# HDSC_HC32F46X register map
Vendor: HDSC Co.,Ltd.; Series: ARMCM4; File version: 1.0
CPU: CM4 r0p1, little endian, MPU, FPU, 4 interrupt priority bits
Registers are 32-bit, read-write, reset 0x0 unless marked. A register's access mark holds for its fields unless they carry their own. Offsets are from the block's base; [hi:lo] are bit positions; {n}, {i} and the like mark numbered series.

## FCM
Base 0x40048400
0x00 LVR
  [15:0] LVR
0x04 UVR
  [15:0] UVR
0x08 CNTR ro
  [15:0] CNTR
0x0C STR
  [0] START
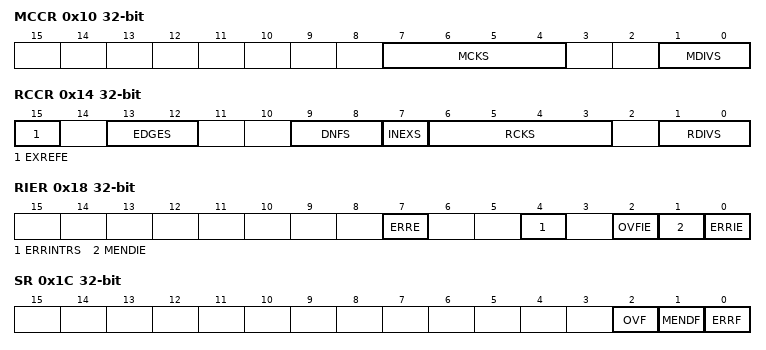
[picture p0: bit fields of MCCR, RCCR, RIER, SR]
0x10 MCCR
  [7:4] MCKS, [1:0] MDIVS
0x14 RCCR
  [15] EXREFE, [13:12] EDGES, [9:8] DNFS, [7] INEXS, [6:3] RCKS, [1:0] RDIVS
0x18 RIER
  [7] ERRE, [4] ERRINTRS, [2] OVFIE, [1] MENDIE, [0] ERRIE
0x1C SR ro
  [2] OVF, [1] MENDF, [0] ERRF
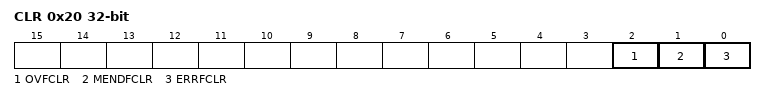
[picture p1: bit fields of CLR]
0x20 CLR wo
  [2] OVFCLR, [1] MENDFCLR, [0] ERRFCLR

## HASH
Base 0x40008400
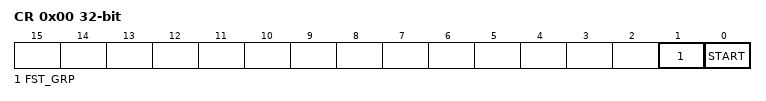
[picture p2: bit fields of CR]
0x00 CR
  [1] FST_GRP, [0] START
0x10 HR7
0x14 HR6
0x18 HR5
0x1C HR4
0x20 HR3
0x24 HR2
0x28 HR1
0x2C HR0
0x40 DR15
0x44 DR14
0x48 DR13
0x4C DR12
0x50 DR11
0x54 DR10
0x58 DR9
0x5C DR8
0x60 DR7
0x64 DR6
0x68 DR5
0x6C DR4
0x70 DR3
0x74 DR2
0x78 DR1
0x7C DR0

## I2C1 — desc I2C
Base 0x4004E000
Same registers: I2C2 0x4004E400, I2C3 0x4004E800
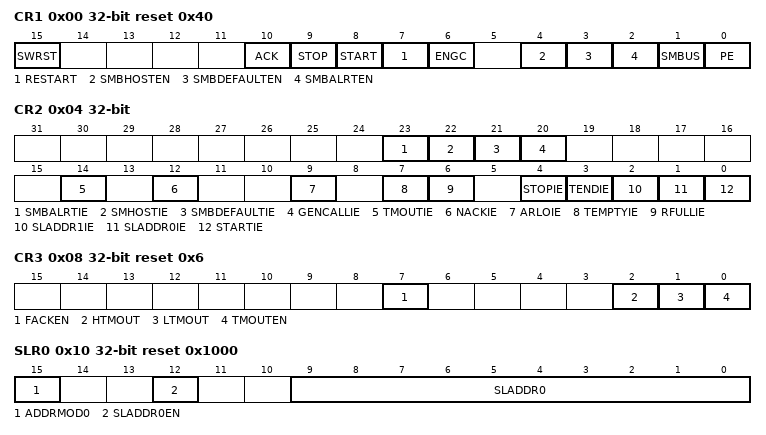
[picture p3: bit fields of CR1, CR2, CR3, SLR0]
0x00 CR1 reset 0x40
  [15] SWRST, [10] ACK, [9] STOP, [8] START, [7] RESTART, [6] ENGC, [4] SMBHOSTEN, [3] SMBDEFAULTEN, [2] SMBALRTEN, [1] SMBUS, [0] PE
0x04 CR2
  [23] SMBALRTIE, [22] SMHOSTIE, [21] SMBDEFAULTIE, [20] GENCALLIE, [14] TMOUTIE, [12] NACKIE, [9] ARLOIE, [7] TEMPTYIE, [6] RFULLIE, [4] STOPIE, [3] TENDIE, [2] SLADDR1IE, [1] SLADDR0IE, [0] STARTIE
0x08 CR3 reset 0x6
  [7] FACKEN, [2] HTMOUT, [1] LTMOUT, [0] TMOUTEN
0x10 SLR0 reset 0x1000
  [15] ADDRMOD0, [12] SLADDR0EN, [9:0] SLADDR0
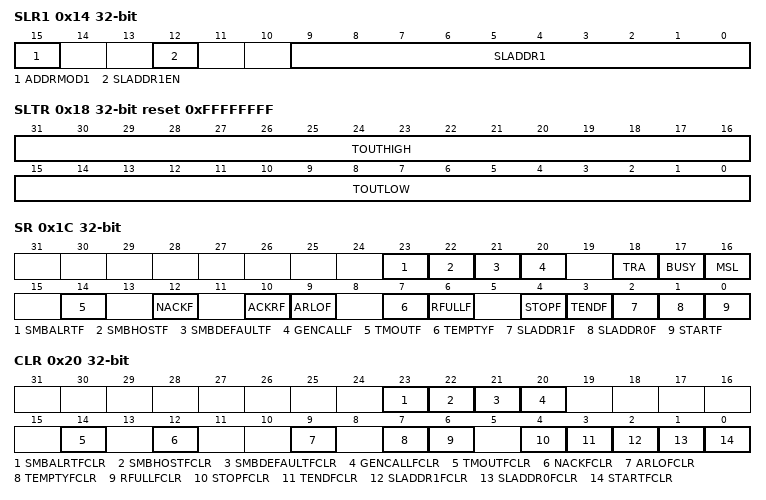
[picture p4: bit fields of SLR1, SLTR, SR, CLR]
0x14 SLR1
  [15] ADDRMOD1, [12] SLADDR1EN, [9:0] SLADDR1
0x18 SLTR reset 0xFFFFFFFF
  [31:16] TOUTHIGH, [15:0] TOUTLOW
0x1C SR
  [23] SMBALRTF, [22] SMBHOSTF, [21] SMBDEFAULTF, [20] GENCALLF, [18] TRA, [17] BUSY, [16] MSL, [14] TMOUTF, [12] NACKF, [10] ACKRF, [9] ARLOF, [7] TEMPTYF, [6] RFULLF, [4] STOPF, [3] TENDF, [2] SLADDR1F, [1] SLADDR0F, [0] STARTF
0x20 CLR wo
  [23] SMBALRTFCLR, [22] SMBHOSTFCLR, [21] SMBDEFAULTFCLR, [20] GENCALLFCLR, [14] TMOUTFCLR, [12] NACKFCLR, [9] ARLOFCLR, [7] TEMPTYFCLR, [6] RFULLFCLR, [4] STOPFCLR, [3] TENDFCLR, [2] SLADDR1FCLR, [1] SLADDR0FCLR, [0] STARTFCLR
0x24 DTR wo reset 0xFF
  [7:0] DT
0x28 DRR ro
  [7:0] DR
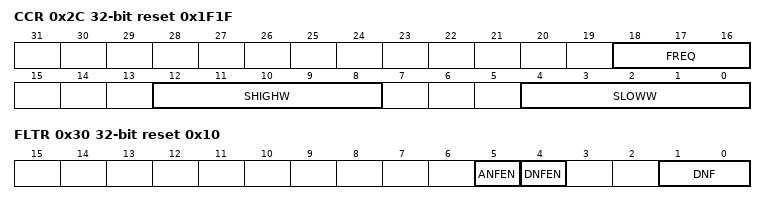
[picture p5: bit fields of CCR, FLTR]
0x2C CCR reset 0x1F1F
  [18:16] FREQ, [12:8] SHIGHW, [4:0] SLOWW
0x30 FLTR reset 0x10
  [5] ANFEN, [4] DNFEN, [1:0] DNF

## I2S1 — desc I2S
Base 0x4001E000
Same registers: I2S2 0x4001E400, I2S3 0x40022000, I2S4 0x40022400
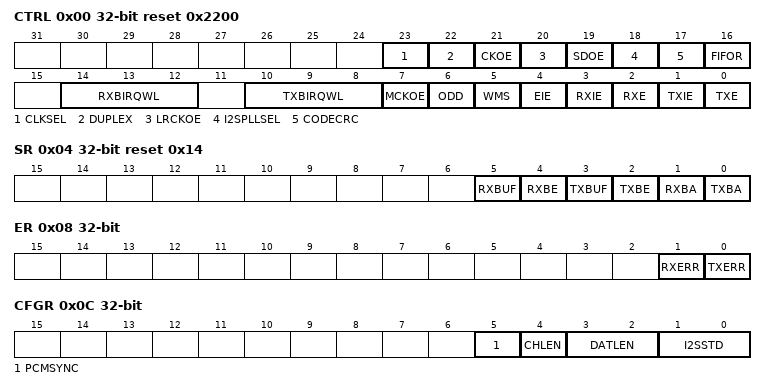
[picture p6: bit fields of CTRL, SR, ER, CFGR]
0x00 CTRL reset 0x2200
  [23] CLKSEL, [22] DUPLEX, [21] CKOE, [20] LRCKOE, [19] SDOE, [18] I2SPLLSEL, [17] CODECRC, [16] FIFOR, [14:12] RXBIRQWL, [10:8] TXBIRQWL, [7] MCKOE, [6] ODD, [5] WMS, [4] EIE, [3] RXIE, [2] RXE, [1] TXIE, [0] TXE
0x04 SR ro reset 0x14
  [5] RXBUF, [4] RXBE, [3] TXBUF, [2] TXBE, [1] RXBA, [0] TXBA
0x08 ER
  [1] RXERR, [0] TXERR
0x0C CFGR
  [5] PCMSYNC, [4] CHLEN, [3:2] DATLEN, [1:0] I2SSTD
0x10 TXBUF wo
0x14 RXBUF ro
0x18 PR reset 0x2
  [7:0] I2SDIV

## ICG
Base 0x00000400
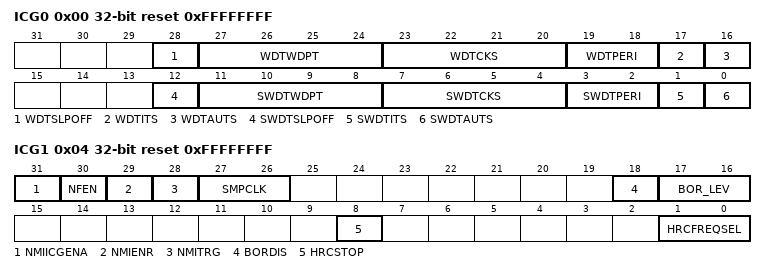
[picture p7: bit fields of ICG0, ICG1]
0x00 ICG0 ro reset 0xFFFFFFFF
  [28] WDTSLPOFF, [27:24] WDTWDPT, [23:20] WDTCKS, [19:18] WDTPERI, [17] WDTITS, [16] WDTAUTS, [12] SWDTSLPOFF, [11:8] SWDTWDPT, [7:4] SWDTCKS, [3:2] SWDTPERI, [1] SWDTITS, [0] SWDTAUTS
0x04 ICG1 ro reset 0xFFFFFFFF
  [31] NMIICGENA, [30] NFEN, [29] NMIENR, [28] NMITRG, [27:26] SMPCLK, [18] BORDIS, [17:16] BOR_LEV, [8] HRCSTOP, [1:0] HRCFREQSEL
{0x0+4i} ICG{i} ro reset 0xFFFFFFFF (i=2..7)

## INTC
Base 0x40051000
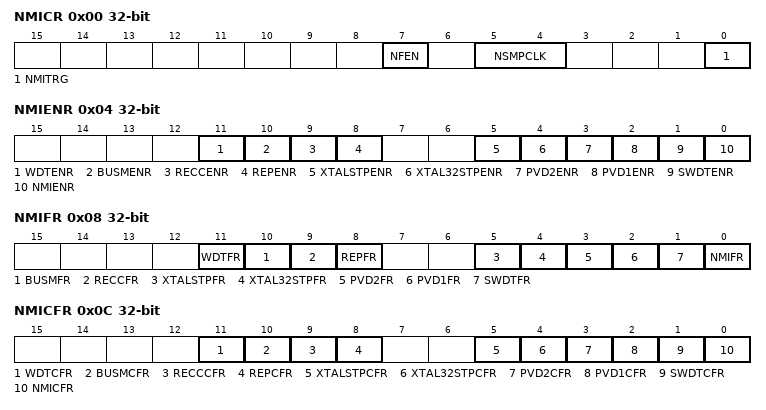
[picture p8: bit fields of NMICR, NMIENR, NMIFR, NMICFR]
0x00 NMICR
  [7] NFEN, [5:4] NSMPCLK, [0] NMITRG
0x04 NMIENR
  [11] WDTENR, [10] BUSMENR, [9] RECCENR, [8] REPENR, [5] XTALSTPENR, [4] XTAL32STPENR, [3] PVD2ENR, [2] PVD1ENR, [1] SWDTENR, [0] NMIENR
0x08 NMIFR
  [11] WDTFR, [10] BUSMFR, [9] RECCFR, [8] REPFR, [5] XTALSTPFR, [4] XTAL32STPFR, [3] PVD2FR, [2] PVD1FR, [1] SWDTFR, [0] NMIFR
0x0C NMICFR
  [11] WDTCFR, [10] BUSMCFR, [9] RECCCFR, [8] REPCFR, [5] XTALSTPCFR, [4] XTAL32STPCFR, [3] PVD2CFR, [2] PVD1CFR, [1] SWDTCFR, [0] NMICFR
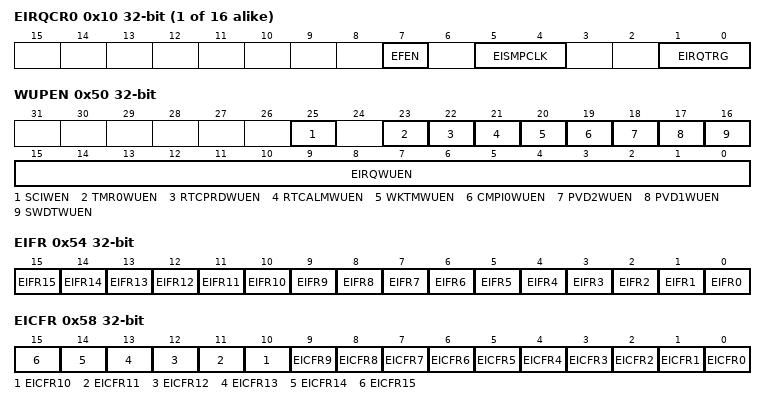
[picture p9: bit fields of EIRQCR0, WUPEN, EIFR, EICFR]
{0x10+4i} EIRQCR{i} (i=0..15)
  [7] EFEN, [5:4] EISMPCLK, [1:0] EIRQTRG
0x50 WUPEN
  [25] SCIWEN, [23] TMR0WUEN, [22] RTCPRDWUEN, [21] RTCALMWUEN, [20] WKTMWUEN, [19] CMPI0WUEN, [18] PVD2WUEN, [17] PVD1WUEN, [16] SWDTWUEN, [15:0] EIRQWUEN
0x54 EIFR
  [n] EIFR{n} (n=0..15)
0x58 EICFR
  [n] EICFR{n} (n=0..15)
{0x5C+4i} SEL{i} reset 0x1FF (i=0..127)
  [8:0] INTSEL
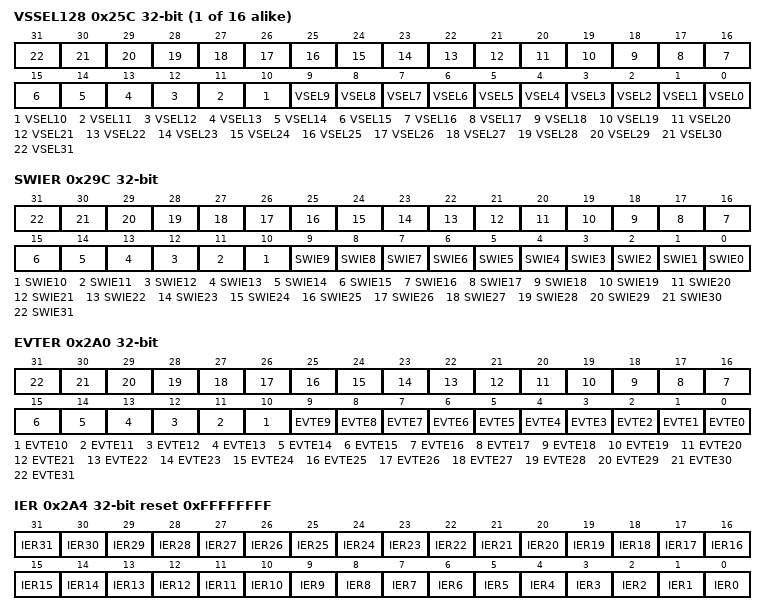
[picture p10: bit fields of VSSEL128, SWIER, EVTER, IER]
{0x5C+4i} VSSEL{i} (i=128..143)
  [n] VSEL{n} (n=0..31)
0x29C SWIER
  [n] SWIE{n} (n=0..31)
0x2A0 EVTER
  [n] EVTE{n} (n=0..31)
0x2A4 IER reset 0xFFFFFFFF
  [n] IER{n} (n=0..31)
